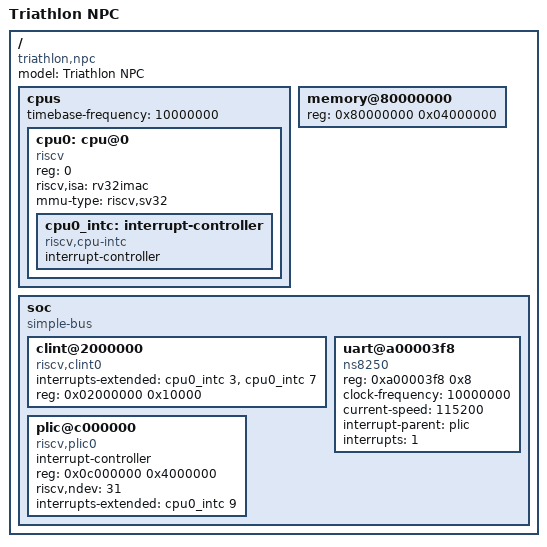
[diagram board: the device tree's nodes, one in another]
/dts-v1/;

/ {
	#address-cells = <1>;
	#size-cells = <1>;
	compatible = "triathlon,npc";
	model = "Triathlon NPC";

	cpus {
		#address-cells = <1>;
		#size-cells = <0>;
		timebase-frequency = <10000000>;

		cpu0: cpu@0 {
			device_type = "cpu";
			reg = <0>;
			status = "okay";
			compatible = "riscv";
			riscv,isa = "rv32imac";
			mmu-type = "riscv,sv32";
			
			cpu0_intc: interrupt-controller {
				#interrupt-cells = <1>;
				interrupt-controller;
				compatible = "riscv,cpu-intc";
			};
		};
	};

	memory@80000000 {
		device_type = "memory";
		reg = <0x80000000 0x04000000>; /* 64MB */
	};

	soc {
		#address-cells = <1>;
		#size-cells = <1>;
		compatible = "simple-bus";
		ranges;

		clint@2000000 {
			compatible = "riscv,clint0";
			interrupts-extended = <&cpu0_intc 3 &cpu0_intc 7>;
			reg = <0x02000000 0x10000>;
		};

		plic@c000000 {
			compatible = "riscv,plic0";
			interrupt-controller;
			#interrupt-cells = <1>;
			reg = <0x0c000000 0x4000000>;
			riscv,ndev = <31>;
			interrupts-extended = <&cpu0_intc 9>;
		};

		uart@a00003f8 {
			compatible = "ns8250";
			reg = <0xa00003f8 0x8>;
			clock-frequency = <10000000>;
			current-speed = <115200>;
			interrupt-parent = <&plic>;
			interrupts = <1>;
		};
	};
};
